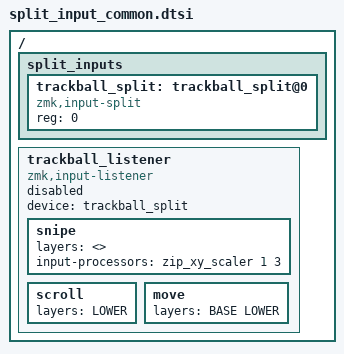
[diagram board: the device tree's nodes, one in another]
#include <dt-bindings/zmk/input_transform.h>
#include <input/processors.dtsi>

#define BASE  0
#define LOWER 1

/ {
  split_inputs {
    #address-cells = <1>;
    #size-cells = <0>;

    trackball_split: trackball_split@0 {
      compatible = "zmk,input-split";
      reg = <0>;
    };
  };

  trackball_listener: trackball_listener {
    compatible = "zmk,input-listener";
    status = "disabled";
    device = <&trackball_split>;

    snipe {
      layers = <>;
      input-processors = <&zip_xy_scaler 1 3>;
    };

    scroll {
      layers = <LOWER>;
    };

    move {
      layers = <BASE LOWER>;
    };
  };
};
